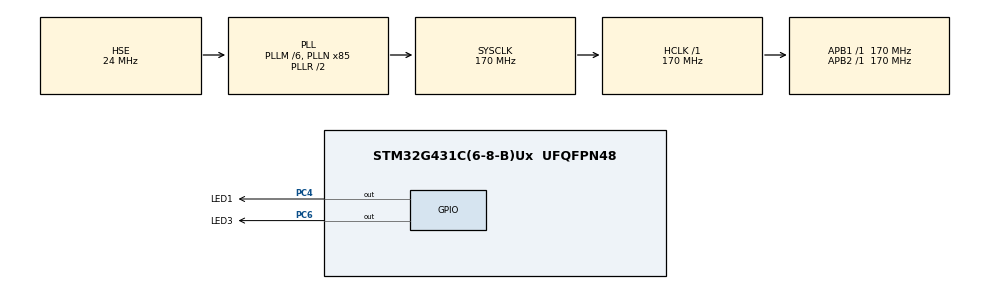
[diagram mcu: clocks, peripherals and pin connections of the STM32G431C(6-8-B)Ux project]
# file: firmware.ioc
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Mcu.Family=STM32G4
Mcu.Name=STM32G431C(6-8-B)Ux
Mcu.Package=UFQFPN48
NVIC.PriorityGroup=NVIC_PRIORITYGROUP_4
PA13.Mode=Serial_Wire
PA13.Signal=SYS_JTMS-SWDIO
PA14.Mode=Serial_Wire
PA14.Signal=SYS_JTCK-SWCLK
PC14-OSC32_IN.Mode=LSE-External-Oscillator
PC14-OSC32_IN.Signal=RCC_OSC32_IN
PC15-OSC32_OUT.Mode=LSE-External-Oscillator
PC15-OSC32_OUT.Signal=RCC_OSC32_OUT
PC4.GPIO_Label=LED1
PC4.PinState=GPIO_PIN_SET
PC4.Signal=GPIO_Output
PC6.GPIO_Label=LED3
PC6.PinState=GPIO_PIN_SET
PC6.Signal=GPIO_Output
PF0-OSC_IN.Mode=HSE-External-Oscillator
PF0-OSC_IN.Signal=RCC_OSC_IN
PF1-OSC_OUT.Mode=HSE-External-Oscillator
PF1-OSC_OUT.Signal=RCC_OSC_OUT
ProjectManager.HeapSize=0x200
ProjectManager.StackSize=0x400
ProjectManager.TargetToolchain=MDK-ARM V5.32
RCC.ADC12Freq_Value=170000000
RCC.AHBFreq_Value=170000000
RCC.APB1Freq_Value=170000000
RCC.APB1TimFreq_Value=170000000
RCC.APB2Freq_Value=170000000
RCC.APB2TimFreq_Value=170000000
RCC.CortexFreq_Value=170000000
RCC.EXTERNAL_CLOCK_VALUE=12288000
RCC.HCLKFreq_Value=170000000
RCC.HSE_VALUE=24000000
RCC.HSI48_VALUE=48000000
RCC.HSI_VALUE=16000000
RCC.PLLM=RCC_PLLM_DIV6
RCC.PLLN=85
RCC.PLLSourceVirtual=RCC_PLLSOURCE_HSE
RCC.SYSCLKFreq_VALUE=170000000
RCC.SYSCLKSource=RCC_SYSCLKSOURCE_PLLCLK
RCC.USBFreq_Value=170000000
RCC.VCOOutputFreq_Value=340000000
VP_SYS_VS_DBSignals.Mode=DisableDeadBatterySignals
board=custom

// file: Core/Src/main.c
/* USER CODE BEGIN Header */
/**
  ******************************************************************************
  * @file           : main.c
  * @brief          : Main program body
  ******************************************************************************
  * @attention
  *
  * Copyright (c) 2026 STMicroelectronics.
  * All rights reserved.
  *
  * This software is licensed under terms that can be found in the LICENSE file
  * in the root directory of this software component.
  * If no LICENSE file comes with this software, it is provided AS-IS.
  *
  ******************************************************************************
  */
/* USER CODE END Header */
#include "main.h"
#include "gpio.h"

/* USER CODE BEGIN PD */
/* LED1 每 500 ms 翻转一次，闪烁周期 1 s。HAL_Delay 按 SysTick 计时，
 * SysTick 来自 SYSCLK，所以周期偏离 1 s 说明 HSE 不是 24 MHz。 */
#define LED_TOGGLE_INTERVAL_MS 500U
/* USER CODE END PD */

void SystemClock_Config(void);

int main(void)
{

  /* MCU Configuration--------------------------------------------------------*/

  /* Reset of all peripherals, Initializes the Flash interface and the Systick. */
  HAL_Init();

  /* Configure the system clock */
  SystemClock_Config();

  /* Initialize all configured peripherals */
  MX_GPIO_Init();

  /* Infinite loop */
  while (1)
  {

    /* USER CODE BEGIN 3 */
    HAL_GPIO_TogglePin(LED1_GPIO_Port, LED1_Pin);
    HAL_Delay(LED_TOGGLE_INTERVAL_MS);
  }
  /* USER CODE END 3 */
}

void SystemClock_Config(void)
{
  RCC_OscInitTypeDef RCC_OscInitStruct = {0};
  RCC_ClkInitTypeDef RCC_ClkInitStruct = {0};

  /** Configure the main internal regulator output voltage
  */
  HAL_PWREx_ControlVoltageScaling(PWR_REGULATOR_VOLTAGE_SCALE1_BOOST);

  /** Initializes the RCC Oscillators according to the specified parameters
  * in the RCC_OscInitTypeDef structure.
  */
  RCC_OscInitStruct.OscillatorType = RCC_OSCILLATORTYPE_HSE;
  RCC_OscInitStruct.HSEState = RCC_HSE_ON;
  RCC_OscInitStruct.PLL.PLLState = RCC_PLL_ON;
  RCC_OscInitStruct.PLL.PLLSource = RCC_PLLSOURCE_HSE;
  RCC_OscInitStruct.PLL.PLLM = RCC_PLLM_DIV6;
  RCC_OscInitStruct.PLL.PLLN = 85;
  RCC_OscInitStruct.PLL.PLLP = RCC_PLLP_DIV2;
  RCC_OscInitStruct.PLL.PLLQ = RCC_PLLQ_DIV2;
  RCC_OscInitStruct.PLL.PLLR = RCC_PLLR_DIV2;
  if (HAL_RCC_OscConfig(&RCC_OscInitStruct) != HAL_OK)
  {
    Error_Handler();
  }

  /** Initializes the CPU, AHB and APB buses clocks
  */
  RCC_ClkInitStruct.ClockType = RCC_CLOCKTYPE_HCLK|RCC_CLOCKTYPE_SYSCLK
                              |RCC_CLOCKTYPE_PCLK1|RCC_CLOCKTYPE_PCLK2;
  RCC_ClkInitStruct.SYSCLKSource = RCC_SYSCLKSOURCE_PLLCLK;
  RCC_ClkInitStruct.AHBCLKDivider = RCC_SYSCLK_DIV1;
  RCC_ClkInitStruct.APB1CLKDivider = RCC_HCLK_DIV1;
  RCC_ClkInitStruct.APB2CLKDivider = RCC_HCLK_DIV1;

  if (HAL_RCC_ClockConfig(&RCC_ClkInitStruct, FLASH_LATENCY_4) != HAL_OK)
  {
    Error_Handler();
  }
}

void Error_Handler(void)
{
  /* USER CODE BEGIN Error_Handler_Debug */
  /* User can add his own implementation to report the HAL error return state */
  __disable_irq();
  /* LED3 常亮表示初始化失败，例如 HSE 起振失败导致 HAL_RCC_OscConfig 出错。
   * 时钟配置失败时 MX_GPIO_Init 还没执行，所以这里重新配置 LED3 引脚。
   * HAL_GPIO_Init 不依赖中断和 SysTick，关中断后调用也可以。 */
  GPIO_InitTypeDef led3 = {0};
  __HAL_RCC_GPIOC_CLK_ENABLE();
  led3.Pin = LED3_Pin;
  led3.Mode = GPIO_MODE_OUTPUT_PP;
  led3.Pull = GPIO_NOPULL;
  led3.Speed = GPIO_SPEED_FREQ_LOW;
  HAL_GPIO_Init(LED3_GPIO_Port, &led3);
  HAL_GPIO_WritePin(LED3_GPIO_Port, LED3_Pin, GPIO_PIN_RESET);
  while (1)
  {
  }
  /* USER CODE END Error_Handler_Debug */
}
